# A31G324 register map
Vendor: ABOV Semiconductor Co., Ltd.; Series: A31G324; File version: 1.0
CPU: CM0PLUS r0p1, little endian, no MPU, no FPU, VTOR, 2 interrupt priority bits
Registers are 32-bit, read-write, reset 0x0 unless marked. A register's access mark holds for its fields unless they carry their own. Offsets are from the block's base; [hi:lo] are bit positions.

## TIMER40 — TIMER COUNTER 40
Base 0x40002800
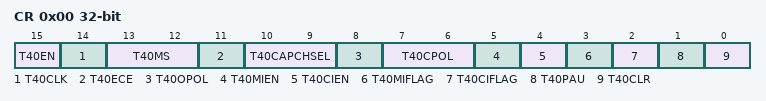
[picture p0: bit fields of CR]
0x00 CR — Timer/Counter 40 Control Register
  [15] T40EN — Timer 40 Operation Enable bit
    0=DISABLE_T40 (Disable timer 40 operation); 1=ENABLE_T40 (Enable timer 40 operation (Counter clear and start))
  [14] T40CLK — Timer 40 Clock Selection bit (Note: This bit should be changed during T40EN bit is "0b".)
    0=SELECT_INTERNAL_CLK (Select an internal prescaler clock); 1=SELECT_EXTERNAL_CLK (Select an external clock)
  [13:12] T40MS — Timer 40 Operation Mode Selection bits (Note: These bits should be changed during T40EN bit is "0b".)
    0=INTERVAL_MODE (Interval mode (All match interrupts can occur)); 1=CAPTURE_MODE (Capture mode (The Period-match interrupt can occur)); 2=BACK_TO_BACK_MODE (Back-to-back mode (All interrupts can occur))
  [11] T40ECE — Timer 40 External Clock Edge Selection bit
  [10:9] T40CAPCHSEL — Timer 40 Capture Channel Selection bits.
  [8] T40OPOL — T40O Polarity Selection bit.
  [7:6] T40CPOL — Timer 40 Capture Polarity Selection bits.
  [5] T40MIEN — Timer 40 Match Interrupt Enable bit.
  [4] T40CIEN — Timer 20 Capture Interrupt Enable bit.
  [3] T40MIFLAG — Timer 40 Match Interrupt Flag bit.
  [2] T40CIFLAG — Timer 40 Capture Interrupt Flag bit.
  [1] T40PAU — Timer 40 Counter Temporary Pause Control bit.
  [0] T40CLR — Timer 40 Counter and Prescaler Clear bit
    0=LET_T40_CNT_BE (No effect); 1=CLEAR_T40_CNT (Clear timer 40 counter and prescaler (Automatically cleared to "0b" after operation))
0x04 ADR reset 0xFFFFFFFF — Timer/Counter 40 A Data Register
  [15:0] ADATA — Timer/Counter 20 A Data bits. The range is 0x0002 to 0xFFFFFFFF.
0x08 BDR reset 0xFFFFFFFF — Timer/Counter 40 B Data Register
  [15:0] BDATA — Timer/Counter 40 B Data bits. The range is 0x0000 to 0xFFFFFFFF.
0x0C CAPDR ro — Timer/Counter 40 Capture Data Register
  [15:0] CAPD — Timer/Counter 40 Capture Data bits.
0x10 PREDR reset 0xFFF — Timer/Counter 40 Prescaler Data Register
  [11:0] PRED — Timer/Counter 40 Prescaler Data bits.
0x14 PREDR2 reset 0xFFF — Timer/Counter 40 Prescaler Data Register 2
  [11:0] PRED — Timer/Counter 40 Prescaler Data bits.
0x18 CNT ro — Timer/Counter 40 Counter Register
  [31:0] CNT — Timer/Counter 40 Counter bits.

## I2C0
Base 0x40004800
Same registers: I2C1 0x40004900
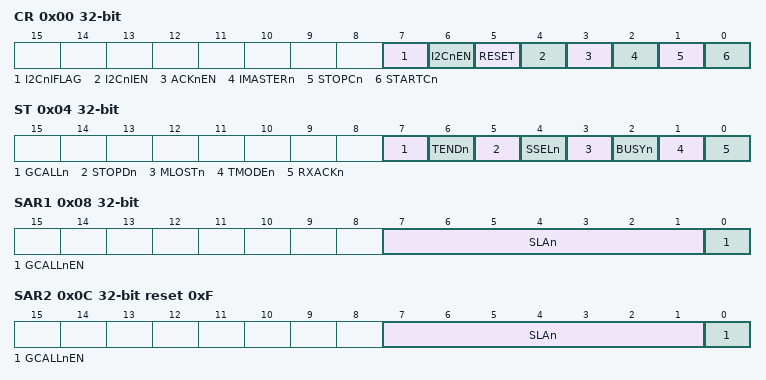
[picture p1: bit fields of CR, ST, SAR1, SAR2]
0x00 CR — I2Cn Control Register
  [7] I2CnIFLAG ro — Interrupt flag bit
  [6] I2CnEN — Activate I2Cn Block ( by supplying clock)
  [5] RESET — Initialize internal register of I2C
  [4] I2CnIEN — I2Cn Interrupt Enable bit.
  [3] ACKnEN — Controls ACK signal generation at ninth SCL period. Notes) ACK signal is output (SDA = 0) for the following 3 cases. Where x = 0 and 1. 1. When received address packet equals to SLAx[6:0] bits in I2CnSARx register. 2. When received address packet equals to value 0x00 with GCALLn enabled. 3. When I2Cn operates as a receiver (master or slave)
  [2] IMASTERn ro — Represent Operation Mode of I2Cn
  [1] STOPCn — STOP Condition Generation When I2Cn is master.
  [0] STARTCn — START Condition Generation When I2Cn is master.
0x04 ST — I2Cn Status Register
  [7] GCALLn — This bit has different meaning depending on whether I2C is master or slave. When I2C is a master, this bit represents whether it received AACK (address ACK) from slave.
  [6] TENDn — This bit is set when 1-byte of data is transferred completely.
  [5] STOPDn — This bit is set when a STOP condition is detected.
  [4] SSELn — This bit is set when I2C is addressed by other master.
  [3] MLOSTn — This bit represents the result of bus arbitration in master mode.
  [2] BUSYn — This bit reflects bus status.
  [1] TMODEn ro — This bit is used to indicate whether I2C is transmitter or receiver.
  [0] RXACKn — This bit shows the state of ACK signal.
0x08 SAR1 — I2Cn Slave Address Register 1
  [7:1] SLAn — These bits configure the slave address 0 in slave mode.
  [0] GCALLnEN — This bit decides whether I2Cn allows general call address 0 or not in I2Cn slave mode.
0x0C SAR2 reset 0xF — I2Cn Slave Address Register 2
  [7:1] SLAn — These bits configure the slave address 1 in slave mode.
  [0] GCALLnEN — This bit decides whether I2Cn allows general call address 1 or not in I2Cn slave mode.
0x10 DR reset 0xF — I2Cn Data Register
  [7:0] DATA — The I2CnDR Transmit buffer and Receive buffer share the same I/O address with this DATA register. The Transmit Data Buffer is the destination for data written to the I2CnDR register. Reading the I2CnDR register returns the contents of the Receive Buffer.
0x14 SDHR reset 0x1 — I2Cn SDA Hold Time Register
  [11:0] HLDT — This register is used to control SDA output timing from the falling edge of SCL. Note that SDA is changed after tPCLK X (I2CnSDHR+2). In master mode, load half the value of I2CnSCLR to this register to make SDA change in the middle of SCL. In slave mode, configure this register regarding the frequency of SCL from master. The SDA is changed after tPCLK X (I2CnSDHR+2) in master mode. So, to insure operation in slave mode, the value tPCLK X (I2CnSDHR + 2) must be smaller than the period of SCL.
0x18 SCLR reset 0xF (reset mask 0xFF) — I2Cn SCL Low Period Register
  [11:0] SCLL — This register defines the low period of SCL in master mode. The base clock is PCLK and the period is calculated by the formula: tPCLK X (4 X I2CnSCLR + 2) where tPCLK is the period of PCLK.
0x1C SCHR reset 0xF (reset mask 0xFF) — I2Cn SCL High Period Register
  [11:0] SCLH — This register defines the high period of SCL in master mode. The base clock is PCLK and the period is calculated by the formula: tPCLK X (4 X I2CnSCHR + 2) where tPCLK is the period of PCLK.
0x20 MR — I2Cn Mode Control Register
  [0] DIS_SDAH — Disable SDA hold time
